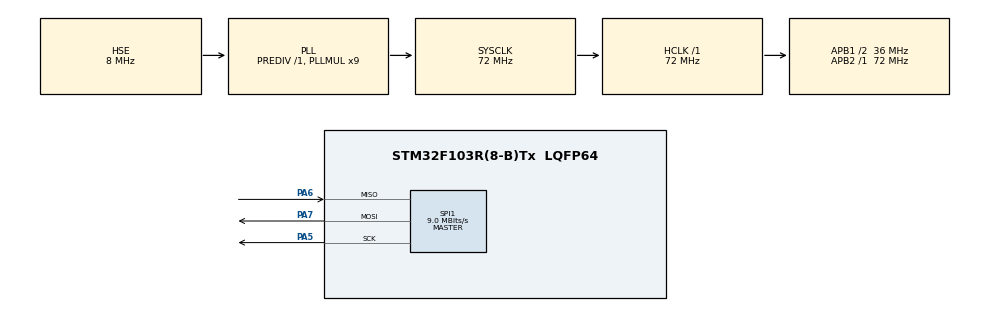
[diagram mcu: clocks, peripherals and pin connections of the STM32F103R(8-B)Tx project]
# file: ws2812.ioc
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Dma.Request0=SPI1_TX
Dma.SPI1_TX.0.Direction=DMA_MEMORY_TO_PERIPH
Dma.SPI1_TX.0.Instance=DMA1_Channel3
Dma.SPI1_TX.0.MemDataAlignment=DMA_MDATAALIGN_BYTE
Dma.SPI1_TX.0.MemInc=DMA_MINC_ENABLE
Dma.SPI1_TX.0.Mode=DMA_NORMAL
Dma.SPI1_TX.0.PeriphDataAlignment=DMA_PDATAALIGN_BYTE
Dma.SPI1_TX.0.PeriphInc=DMA_PINC_DISABLE
Dma.SPI1_TX.0.Priority=DMA_PRIORITY_LOW
Mcu.Family=STM32F1
Mcu.Name=STM32F103R(8-B)Tx
Mcu.Package=LQFP64
NVIC.DMA1_Channel3_IRQn=true\:0\:0\:false\:false\:true\:false
NVIC.PriorityGroup=NVIC_PRIORITYGROUP_4
NVIC.SPI1_IRQn=true\:0\:0\:false\:false\:true\:true
PA13.Mode=Serial_Wire
PA13.Signal=SYS_JTMS-SWDIO
PA14.Mode=Serial_Wire
PA14.Signal=SYS_JTCK-SWCLK
PA5.Mode=Full_Duplex_Master
PA5.Signal=SPI1_SCK
PA6.Mode=Full_Duplex_Master
PA6.Signal=SPI1_MISO
PA7.Mode=Full_Duplex_Master
PA7.Signal=SPI1_MOSI
PD0-OSC_IN.Mode=HSE-External-Oscillator
PD0-OSC_IN.Signal=RCC_OSC_IN
PD1-OSC_OUT.Mode=HSE-External-Oscillator
PD1-OSC_OUT.Signal=RCC_OSC_OUT
ProjectManager.HeapSize=0x200
ProjectManager.StackSize=0x400
ProjectManager.TargetToolchain=MDK-ARM V5
RCC.AHBFreq_Value=72000000
RCC.APB1CLKDivider=RCC_HCLK_DIV2
RCC.APB1Freq_Value=36000000
RCC.APB1TimFreq_Value=72000000
RCC.APB2Freq_Value=72000000
RCC.APB2TimFreq_Value=72000000
RCC.HCLKFreq_Value=72000000
RCC.PLLMUL=RCC_PLL_MUL9
RCC.PLLSourceVirtual=RCC_PLLSOURCE_HSE
RCC.SYSCLKFreq_VALUE=72000000
RCC.SYSCLKSource=RCC_SYSCLKSOURCE_PLLCLK
RCC.USBFreq_Value=72000000
SPI1.BaudRatePrescaler=SPI_BAUDRATEPRESCALER_8
SPI1.CalculateBaudRate=9.0 MBits/s
SPI1.Direction=SPI_DIRECTION_2LINES
SPI1.Mode=SPI_MODE_MASTER
SPI1.VirtualType=VM_MASTER
board=ws2812

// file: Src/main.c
/**
  ******************************************************************************
  * File Name          : main.c
  * Description        : Main program body
  ******************************************************************************
  ** This notice applies to any and all portions of this file
  * that are not between comment pairs USER CODE BEGIN and
  * USER CODE END. Other portions of this file, whether
  * inserted by the user or by software development tools
  * are owned by their respective copyright owners.
  *
  * COPYRIGHT(c) 2018 STMicroelectronics
  *
  * Redistribution and use in source and binary forms, with or without modification,
  * are permitted provided that the following conditions are met:
  *   1. Redistributions of source code must retain the above copyright notice,
  *      this list of conditions and the following disclaimer.
  *   2. Redistributions in binary form must reproduce the above copyright notice,
  *      this list of conditions and the following disclaimer in the documentation
  *      and/or other materials provided with the distribution.
  *   3. Neither the name of STMicroelectronics nor the names of its contributors
  *      may be used to endorse or promote products derived from this software
  *      without specific prior written permission.
  *
  * THIS SOFTWARE IS PROVIDED BY THE COPYRIGHT HOLDERS AND CONTRIBUTORS "AS IS"
  * AND ANY EXPRESS OR IMPLIED WARRANTIES, INCLUDING, BUT NOT LIMITED TO, THE
  * IMPLIED WARRANTIES OF MERCHANTABILITY AND FITNESS FOR A PARTICULAR PURPOSE ARE
  * DISCLAIMED. IN NO EVENT SHALL THE COPYRIGHT HOLDER OR CONTRIBUTORS BE LIABLE
  * FOR ANY DIRECT, INDIRECT, INCIDENTAL, SPECIAL, EXEMPLARY, OR CONSEQUENTIAL
  * DAMAGES (INCLUDING, BUT NOT LIMITED TO, PROCUREMENT OF SUBSTITUTE GOODS OR
  * SERVICES; LOSS OF USE, DATA, OR PROFITS; OR BUSINESS INTERRUPTION) HOWEVER
  * CAUSED AND ON ANY THEORY OF LIABILITY, WHETHER IN CONTRACT, STRICT LIABILITY,
  * OR TORT (INCLUDING NEGLIGENCE OR OTHERWISE) ARISING IN ANY WAY OUT OF THE USE
  * OF THIS SOFTWARE, EVEN IF ADVISED OF THE POSSIBILITY OF SUCH DAMAGE.
  *
  ******************************************************************************
  */

#include "main.h"
#include "stm32f1xx_hal.h"

/* USER CODE BEGIN Includes */
#include "ws28xx.h"
/* USER CODE END Includes */

SPI_HandleTypeDef hspi1;
DMA_HandleTypeDef hdma_spi1_tx;

/* USER CODE BEGIN PV */
/* Private variables ---------------------------------------------------------*/

/* USER CODE END PV */

void SystemClock_Config(void);
static void MX_GPIO_Init(void);
static void MX_DMA_Init(void);
static void MX_SPI1_Init(void);

/* USER CODE BEGIN PFP */
/* Private function prototypes -----------------------------------------------*/

/* USER CODE END PFP */

int main(void)
{

  /* MCU Configuration----------------------------------------------------------*/

  /* Reset of all peripherals, Initializes the Flash interface and the Systick. */
  HAL_Init();

  /* Configure the system clock */
  SystemClock_Config();

  /* Initialize all configured peripherals */
  MX_GPIO_Init();
  MX_DMA_Init();
  MX_SPI1_Init();

  /* USER CODE BEGIN 2 */
	ws28xx_init();
	//ws28xx_test();
//	ws28xx_SetColor(0,ws28xx_Color_Red);
//	ws28xx_SetColor(3,ws28xx_Color_Teal);
//	ws28xx_SetColorArray(5,7,ws28xx_Color_Teal);
//	ws28xx_Update();
  /* USER CODE END 2 */

  /* Infinite loop */
  while (1)
  {

		for(int i = 0; i<9;i++){

		ws28xx_SetColor(i,ws28xx_Color_Pruple);
			//ws28xx_SetColor(i+1,ws28xx_Color_Red);
	//	ws28xx_SetColor(i+1,ws28xx_Color_Blue);
		ws28xx_Update();
		HAL_Delay(5);
		ws28xx_SetColor(i,ws28xx_Color_Black);
		}
		//ws28xx_SetColorArrayAndOtherOff(0,8,ws28xx_Color_Black);
	//	ws28xx_Update();
		HAL_Delay(1000);
		for(int b = 9; b>0;b--){

		ws28xx_SetColor(b,ws28xx_Color_Aqua);
	//	ws28xx_SetColor(i+1,ws28xx_Color_Blue);
		ws28xx_Update();
		HAL_Delay(5);
		ws28xx_SetColor(b,ws28xx_Color_Black);
		}

//	for(int i=0;i<255;i++)
//	{	for(int b=0;b<255;b++)
//			{
//			ws28xx_SetColorRGB(1,i,0,b);
//			ws28xx_Update();
//			}
//			ws28xx_SetColorRGB(2,i,0,0);
//	}
  }

}

/** System Clock Configuration
*/
void SystemClock_Config(void)
{

  RCC_OscInitTypeDef RCC_OscInitStruct;
  RCC_ClkInitTypeDef RCC_ClkInitStruct;

    /**Initializes the CPU, AHB and APB busses clocks
    */
  RCC_OscInitStruct.OscillatorType = RCC_OSCILLATORTYPE_HSE;
  RCC_OscInitStruct.HSEState = RCC_HSE_ON;
  RCC_OscInitStruct.HSEPredivValue = RCC_HSE_PREDIV_DIV1;
  RCC_OscInitStruct.HSIState = RCC_HSI_ON;
  RCC_OscInitStruct.PLL.PLLState = RCC_PLL_ON;
  RCC_OscInitStruct.PLL.PLLSource = RCC_PLLSOURCE_HSE;
  RCC_OscInitStruct.PLL.PLLMUL = RCC_PLL_MUL9;
  if (HAL_RCC_OscConfig(&RCC_OscInitStruct) != HAL_OK)
  {
    _Error_Handler(__FILE__, __LINE__);
  }

    /**Initializes the CPU, AHB and APB busses clocks
    */
  RCC_ClkInitStruct.ClockType = RCC_CLOCKTYPE_HCLK|RCC_CLOCKTYPE_SYSCLK
                              |RCC_CLOCKTYPE_PCLK1|RCC_CLOCKTYPE_PCLK2;
  RCC_ClkInitStruct.SYSCLKSource = RCC_SYSCLKSOURCE_PLLCLK;
  RCC_ClkInitStruct.AHBCLKDivider = RCC_SYSCLK_DIV1;
  RCC_ClkInitStruct.APB1CLKDivider = RCC_HCLK_DIV2;
  RCC_ClkInitStruct.APB2CLKDivider = RCC_HCLK_DIV1;

  if (HAL_RCC_ClockConfig(&RCC_ClkInitStruct, FLASH_LATENCY_2) != HAL_OK)
  {
    _Error_Handler(__FILE__, __LINE__);
  }

    /**Configure the Systick interrupt time
    */
  HAL_SYSTICK_Config(HAL_RCC_GetHCLKFreq()/1000);

    /**Configure the Systick
    */
  HAL_SYSTICK_CLKSourceConfig(SYSTICK_CLKSOURCE_HCLK);

  /* SysTick_IRQn interrupt configuration */
  HAL_NVIC_SetPriority(SysTick_IRQn, 0, 0);
}

/* SPI1 init function */
static void MX_SPI1_Init(void)
{

  /* SPI1 parameter configuration*/
  hspi1.Instance = SPI1;
  hspi1.Init.Mode = SPI_MODE_MASTER;
  hspi1.Init.Direction = SPI_DIRECTION_2LINES;
  hspi1.Init.DataSize = SPI_DATASIZE_8BIT;
  hspi1.Init.CLKPolarity = SPI_POLARITY_LOW;
  hspi1.Init.CLKPhase = SPI_PHASE_1EDGE;
  hspi1.Init.NSS = SPI_NSS_SOFT;
  hspi1.Init.BaudRatePrescaler = SPI_BAUDRATEPRESCALER_8;
  hspi1.Init.FirstBit = SPI_FIRSTBIT_MSB;
  hspi1.Init.TIMode = SPI_TIMODE_DISABLE;
  hspi1.Init.CRCCalculation = SPI_CRCCALCULATION_DISABLE;
  hspi1.Init.CRCPolynomial = 10;
  if (HAL_SPI_Init(&hspi1) != HAL_OK)
  {
    _Error_Handler(__FILE__, __LINE__);
  }

}

static void MX_DMA_Init(void)
{
  /* DMA controller clock enable */
  __HAL_RCC_DMA1_CLK_ENABLE();

  /* DMA interrupt init */
  /* DMA1_Channel3_IRQn interrupt configuration */
  HAL_NVIC_SetPriority(DMA1_Channel3_IRQn, 0, 0);
  HAL_NVIC_EnableIRQ(DMA1_Channel3_IRQn);

}

/** Configure pins as
        * Analog
        * Input
        * Output
        * EVENT_OUT
        * EXTI
*/
static void MX_GPIO_Init(void)
{

  /* GPIO Ports Clock Enable */
  __HAL_RCC_GPIOD_CLK_ENABLE();
  __HAL_RCC_GPIOA_CLK_ENABLE();

}

void _Error_Handler(char * file, int line)
{
  while(1)
  {
  }
}

/************************ (C) COPYRIGHT STMicroelectronics *****END OF FILE****/
